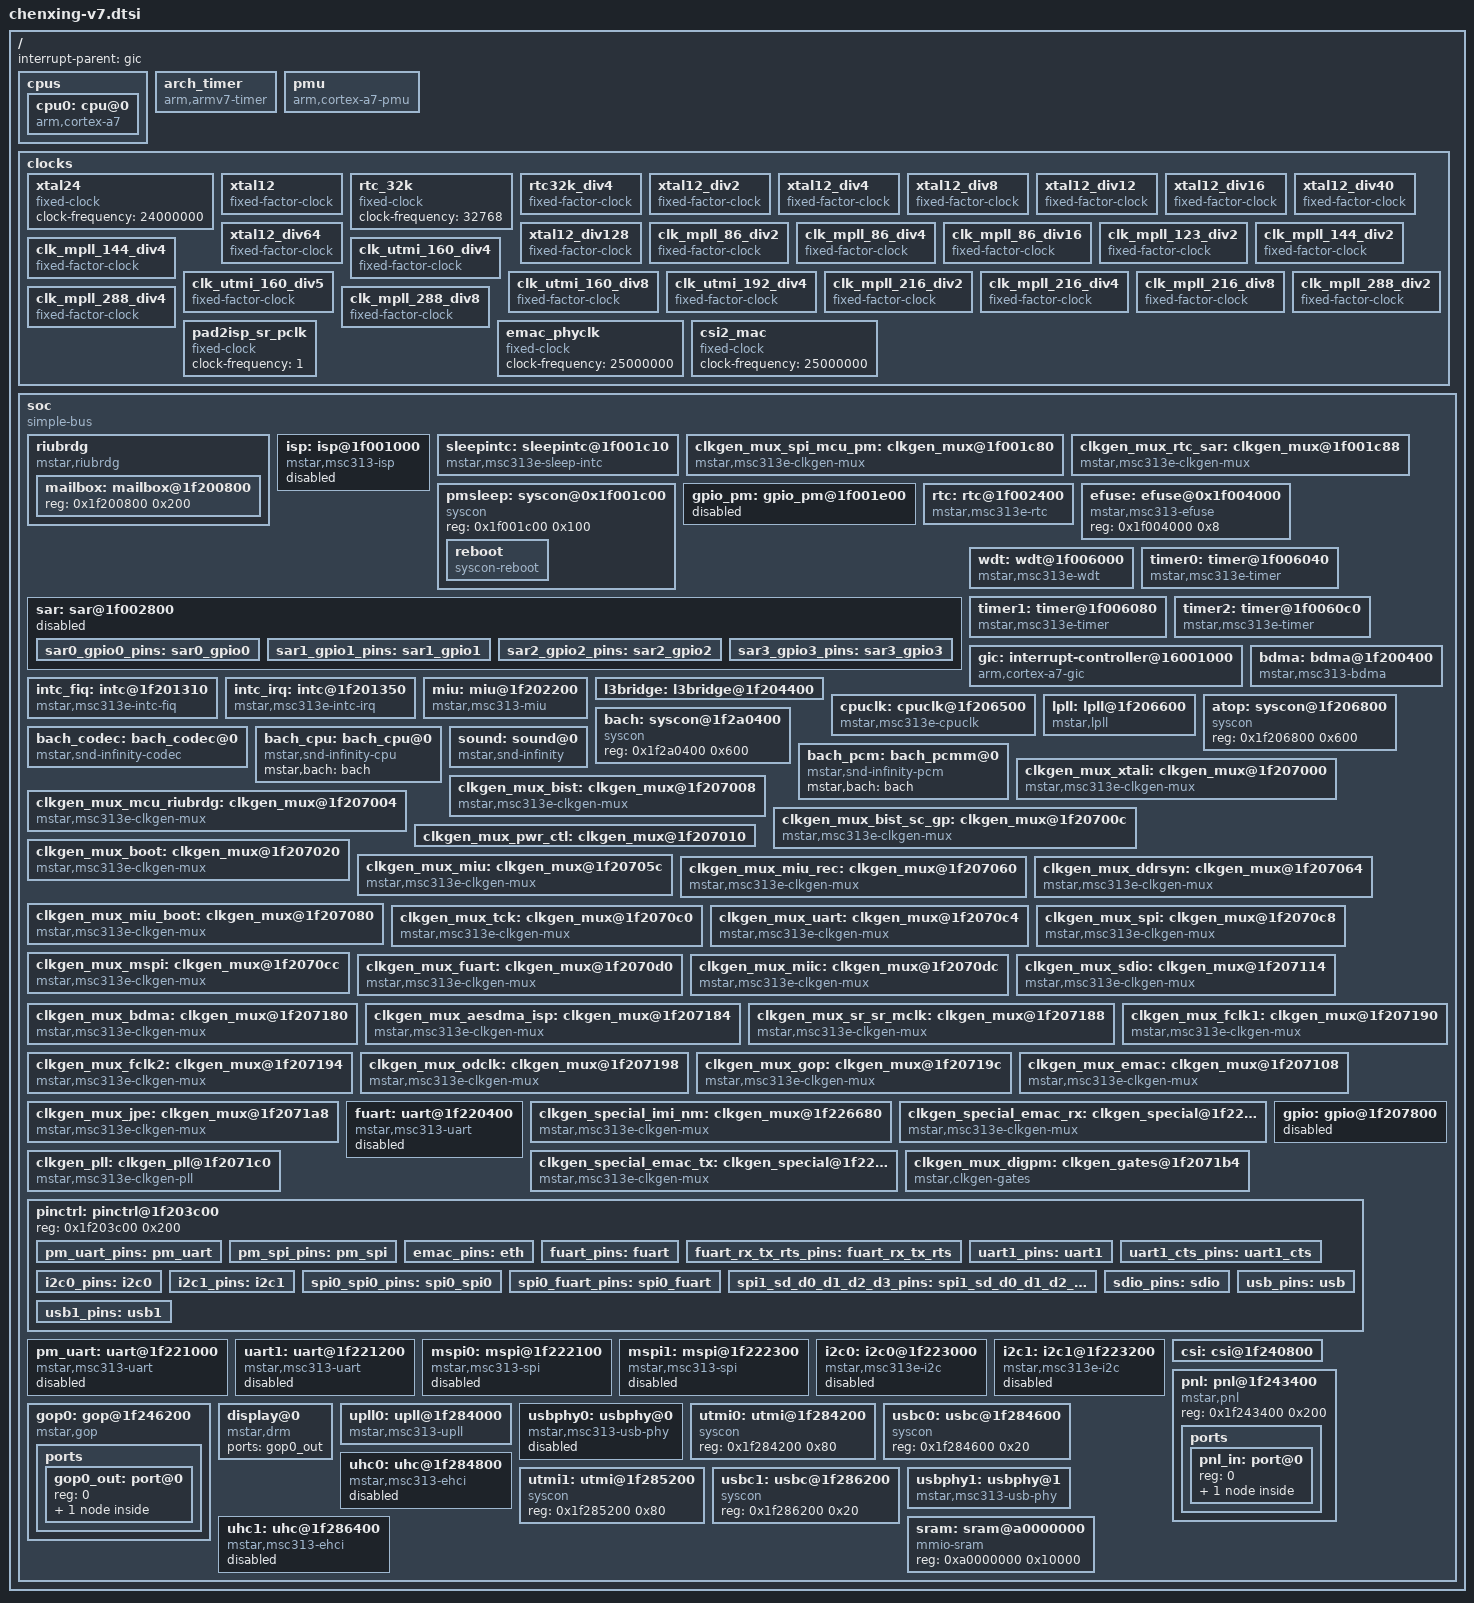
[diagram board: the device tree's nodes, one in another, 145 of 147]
// SPDX-License-Identifier: GPL-2.0
/*
 * Copyright (c) 2019 thingy.jp.
 * Author: Daniel Palmer <daniel@thingy.jp>
 */

#include <dt-bindings/interrupt-controller/irq.h>
#include <dt-bindings/interrupt-controller/arm-gic.h>
#include <dt-bindings/clock/mstar.h>

/ {
	#address-cells = <1>;
	#size-cells = <1>;
	interrupt-parent = <&gic>;

	cpus {
		#address-cells = <1>;
		#size-cells = <0>;

		cpu0: cpu@0 {
			device_type = "cpu";
			compatible = "arm,cortex-a7";
			reg = <0x0>;
			clocks = <&cpuclk>;
			clock-names = "cpuclk";
		};
	};

	arch_timer {
		compatible = "arm,armv7-timer";
		interrupts = <GIC_PPI 13 (GIC_CPU_MASK_SIMPLE(2)
				| IRQ_TYPE_LEVEL_LOW)>,
			     <GIC_PPI 14 (GIC_CPU_MASK_SIMPLE(2)
				| IRQ_TYPE_LEVEL_LOW)>,
			     <GIC_PPI 11 (GIC_CPU_MASK_SIMPLE(2)
				| IRQ_TYPE_LEVEL_LOW)>,
			     <GIC_PPI 10 (GIC_CPU_MASK_SIMPLE(2)
				| IRQ_TYPE_LEVEL_LOW)>;
		clock-frequency = <6000000>;
	};

	pmu {
		compatible = "arm,cortex-a7-pmu";
		interrupts = <GIC_SPI 10 IRQ_TYPE_LEVEL_HIGH>,
			     <GIC_SPI 16 IRQ_TYPE_LEVEL_HIGH>,
			     <GIC_SPI 22 IRQ_TYPE_LEVEL_HIGH>,
			     <GIC_SPI 28 IRQ_TYPE_LEVEL_HIGH>;
	};

	clocks: clocks {
		/*
		 * For the msc313e there is only a 24mhz clock input so everything else must come
		 * from this base clock unless there are some on-die oscillators that aren't mentioned
		 * anywhere.
		 */
		xtal24: xtal24 {
			#clock-cells = <0>;
			compatible = "fixed-clock";
			clock-frequency = <24000000>;
		};

		xtal12: xtal12 {
			#clock-cells = <0>;
			compatible = "fixed-factor-clock";
			clocks = <&xtal24>;
			clock-div = <2>;
			clock-mult = <1>;
		};

		rtc_32k: rtc_32k {
			#clock-cells = <0>;
			compatible = "fixed-clock";
			clock-frequency = <32768>;
		};

		rtc32k_div4: rtc32k_div4 {
			compatible = "fixed-factor-clock";
			#clock-cells = <0>;
			clocks = <&rtc_32k>;
			clock-div = <4>;
			clock-mult = <1>;
		};

		xtal12_div2: xtal12_div2 {
			compatible = "fixed-factor-clock";
			#clock-cells = <0>;
			clocks = <&xtal12>;
			clock-div = <2>;
			clock-mult = <1>;
		};

		xtal12_div4: xtal12_div4 {
			compatible = "fixed-factor-clock";
			#clock-cells = <0>;
			clocks = <&xtal12>;
			clock-div = <4>;
			clock-mult = <1>;
		};

		xtal12_div8: xtal12_div8 {
			compatible = "fixed-factor-clock";
			#clock-cells = <0>;
			clocks = <&xtal12>;
			clock-div = <8>;
			clock-mult = <1>;
		};

		xtal12_div12: xtal12_div12 {
			compatible = "fixed-factor-clock";
			#clock-cells = <0>;
			clocks = <&xtal12>;
			clock-div = <12>;
			clock-mult = <1>;
		};

		xtal12_div16: xtal12_div16 {
			compatible = "fixed-factor-clock";
			#clock-cells = <0>;
			clocks = <&xtal12>;
			clock-div = <16>;
			clock-mult = <1>;
		};

		xtal12_div40: xtal12_div40 {
			compatible = "fixed-factor-clock";
			#clock-cells = <0>;
			clocks = <&xtal12>;
			clock-div = <40>;
			clock-mult = <1>;
		};

		xtal12_div64: xtal12_div64 {
			compatible = "fixed-factor-clock";
			#clock-cells = <0>;
			clocks = <&xtal12>;
			clock-div = <64>;
			clock-mult = <1>;
		};

		xtal12_div128: xtal12_div128 {
			compatible = "fixed-factor-clock";
			#clock-cells = <0>;
			clocks = <&xtal12>;
			clock-div = <128>;
			clock-mult = <1>;
		};

		clk_mpll_86_div2: clk_mpll_86_div2 {
			compatible = "fixed-factor-clock";
			#clock-cells = <0>;
			clocks = <&clkgen_pll MSTAR_MPLL_GATE_MPLL_86>;
			clock-div = <2>;
			clock-mult = <1>;
		};

		clk_mpll_86_div4: clk_mpll_86_div4 {
			compatible = "fixed-factor-clock";
			#clock-cells = <0>;
			clocks = <&clkgen_pll MSTAR_MPLL_GATE_MPLL_86>;
			clock-div = <4>;
			clock-mult = <1>;
		};

		clk_mpll_86_div16: clk_mpll_86_div16 {
			compatible = "fixed-factor-clock";
			#clock-cells = <0>;
			clocks = <&clkgen_pll MSTAR_MPLL_GATE_MPLL_86>;
			clock-div = <16>;
			clock-mult = <1>;
		};

		clk_mpll_123_div2: clk_mpll_123_div2 {
			compatible = "fixed-factor-clock";
			#clock-cells = <0>;
			clocks = <&clkgen_pll MSTAR_MPLL_GATE_MPLL_123>;
			clock-div = <2>;
			clock-mult = <1>;
		};

		clk_mpll_144_div2: clk_mpll_144_div2 {
			compatible = "fixed-factor-clock";
			#clock-cells = <0>;
			clocks = <&clkgen_pll MSTAR_MPLL_GATE_MPLL_144>;
			clock-div = <2>;
			clock-mult = <1>;
		};

		clk_mpll_144_div4: clk_mpll_144_div4 {
			compatible = "fixed-factor-clock";
			#clock-cells = <0>;
			clocks = <&clkgen_pll MSTAR_MPLL_GATE_MPLL_144>;
			clock-div = <4>;
			clock-mult = <1>;
		};

		clk_utmi_160_div4: clk_utmi_160_div4 {
			compatible = "fixed-factor-clock";
			#clock-cells = <0>;
			clocks = <&clkgen_pll MSTAR_MPLL_GATE_UTMI_160>;
			clock-div = <4>;
			clock-mult = <1>;
		};

		clk_utmi_160_div5: clk_utmi_160_div5 {
			compatible = "fixed-factor-clock";
			#clock-cells = <0>;
			clocks = <&clkgen_pll MSTAR_MPLL_GATE_UTMI_160>;
			clock-div = <5>;
			clock-mult = <1>;
		};

		clk_utmi_160_div8: clk_utmi_160_div8 {
			compatible = "fixed-factor-clock";
			#clock-cells = <0>;
			clocks = <&clkgen_pll MSTAR_MPLL_GATE_UTMI_160>;
			clock-div = <8>;
			clock-mult = <1>;
		};

		clk_utmi_192_div4: clk_utmi_192_div4 {
			compatible = "fixed-factor-clock";
			#clock-cells = <0>;
			clocks = <&clkgen_pll MSTAR_MPLL_GATE_UTMI_192>;
			clock-div = <4>;
			clock-mult = <1>;
		};

		clk_mpll_216_div2: clk_mpll_216_div2 {
			compatible = "fixed-factor-clock";
			#clock-cells = <0>;
			clocks = <&clkgen_pll MSTAR_MPLL_GATE_MPLL_216>;
			clock-div = <2>;
			clock-mult = <1>;
		};

		clk_mpll_216_div4: clk_mpll_216_div4 {
			compatible = "fixed-factor-clock";
			#clock-cells = <0>;
			clocks = <&clkgen_pll MSTAR_MPLL_GATE_MPLL_216>;
			clock-div = <4>;
			clock-mult = <1>;
		};

		clk_mpll_216_div8: clk_mpll_216_div8 {
			compatible = "fixed-factor-clock";
			#clock-cells = <0>;
			clocks = <&clkgen_pll MSTAR_MPLL_GATE_MPLL_216>;
			clock-div = <8>;
			clock-mult = <1>;
		};

		clk_mpll_288_div2: clk_mpll_288_div2 {
			compatible = "fixed-factor-clock";
			#clock-cells = <0>;
			clocks = <&clkgen_pll MSTAR_MPLL_GATE_MPLL_288>;
			clock-div = <2>;
			clock-mult = <1>;
		};

		clk_mpll_288_div4: clk_mpll_288_div4 {
			compatible = "fixed-factor-clock";
			#clock-cells = <0>;
			clocks = <&clkgen_pll MSTAR_MPLL_GATE_MPLL_288>;
			clock-div = <4>;
			clock-mult = <1>;
		};

		clk_mpll_288_div8: clk_mpll_288_div8 {
			compatible = "fixed-factor-clock";
			#clock-cells = <0>;
			clocks = <&clkgen_pll MSTAR_MPLL_GATE_MPLL_288>;
			clock-div = <8>;
			clock-mult = <1>;
		};

		emac_phyclk: emac_phyclk {
			#clock-cells = <0>;
			compatible = "fixed-clock";
			clock-frequency = <25000000>;
		};
		
		pad2isp_sr_pclk: pad2isp_sr_pclk {
			#clock-cells = <0>;
			compatible = "fixed-clock";
			clock-frequency = <1>;
		};
	
		csi2_mac: csi2_mac {
			#clock-cells = <0>;
			compatible = "fixed-clock";
			clock-frequency = <25000000>;
		};
	};

	soc: soc {
		compatible = "simple-bus";
		#address-cells = <1>;
		#size-cells = <1>;
		ranges;

		riubrdg: riubrdg {
			compatible = "mstar,riubrdg";
			#address-cells = <1>;
			#size-cells = <1>;
			ranges;
			clocks = <&clkgen_mux_mcu_riubrdg 1>;
			interrupts-extended = <&intc_irq 51 IRQ_TYPE_LEVEL_HIGH>;

			mailbox: mailbox@1f200800 {
				reg = <0x1f200800 0x200>;
				/*
				 * 0x0 - boot rom writes 0xbabe here right near the start.
				 */
			};
		};

		isp: isp@1f001000 {
			compatible = "mstar,msc313-isp";
			reg = <0x1f001000 0x400>,
			      <0x1f002c00 0x200>,
			      <0x1f002e00 0x200>,
			      <0x14000000 0x1000000>;
			clocks = <&clkgen_mux_aesdma_isp 1>;
			interrupts-extended = <&intc_irq 5 IRQ_TYPE_LEVEL_HIGH>;
			dmas = <&bdma 0>, <&bdma 1>;
			dma-names = "qspi", "qspi";
			pinctrl-names = "default";
			pinctrl-0 = <&pm_spi_pins>;
			status = "disabled";
		};

		sleepintc: sleepintc@1f001c10 {
			compatible = "mstar,msc313e-sleep-intc";
			reg = <0x1f001c10 0x8>;
			interrupts-extended = <&intc_irq 2 IRQ_TYPE_LEVEL_HIGH>;
			interrupt-controller;
			#interrupt-cells = <2>;
		};

		clkgen_mux_spi_mcu_pm: clkgen_mux@1f001c80 {
			compatible = "mstar,msc313e-clkgen-mux";
			reg = <0x1f001c80 0x4>;
			#clock-cells = <1>;
			clock-output-names = "mcu_pm", "spi_pm";
			shifts = <0>, <8>;
			mux-shifts = <2>, <10>;
			mux-widths = <4>, <4>;
			mux-ranges = <0 1>, <1 16>;
			clocks = /* mcu_pm */
				 <&clkgen_pll MSTAR_MPLL_GATE_MPLL_216>,
				 /* spi_pm */
				 <&rtc_32k>,
				 <&clk_mpll_216_div8>,
				 <&clk_mpll_144_div4>,
				 <&clk_mpll_86_div2>,
				 <&clk_mpll_216_div4>,
				 <&clk_mpll_144_div2>,
				 <&clkgen_pll MSTAR_MPLL_GATE_MPLL_86>,
				 <&clk_mpll_216_div2>,
				 <&xtal12_div8>,
				 <&xtal12_div12>,
				 <&rtc32k_div4>,
				 <&xtal12_div16>,
				 <&xtal12_div2>,
				 <&xtal12_div4>,
				 <&xtal12>,
				 <&xtal24>;
		};

		clkgen_mux_rtc_sar: clkgen_mux@1f001c88 {
			compatible = "mstar,msc313e-clkgen-mux";
			reg = <0x1f001c88 0x4>;
			#clock-cells = <1>;
			clock-output-names = "rtc", "sar", "pm_sleep";
			shifts = <0>, <5>, <10>;
			mux-shifts = <2>, <7>, <12>;
			mux-widths = <2>, <3>, <3>;
			mux-ranges = <0 2>, <0 8>, <0 8>;
			clocks = <&clkgen_mux_xtali 0>,
					 <&rtc_32k>,
					 <&xtal12_div8>,
					 <&xtal12_div12>,
					 <&rtc32k_div4>,
					 <&xtal12_div16>,
					 <&xtal12_div2>,
					 <&xtal12_div4>;
		};

		pmsleep: syscon@0x1f001c00 {
			/* msc313e notes */
			/* 0x1f001c00 - wake up source */
			/*
			 * 1f001c24 -- bit 11 disables pm uart rx
			 * -- bit 15 is set when going into deep sleep
			 *
			 * mysteryclk1 1f001cf4
			 * 0x1f001cc0 -- ??
			 * 0x1f001cc8  -- set to 9fe8 before deep sleep
			 * 0x1f001ccc  -- set to 9fe8 before deep sleep
			 * 0x1f001cdc  -- set to 0xa5 before deep sleep
		         *
			 * 0x1f001c70  -- set to 0x0c before deep sleep
			 * 0x1f001c48  -- set to 0xbabe before deep sleep
			 *
			 * 0x1f001cec -- return address after resume
			 * 0x1f001cf0
			 * 0x1f001cf4 -- clk for timers?
			 * 0x1f001cb8 - writing 0x79 triggers a cpu reset
			 * 0x1f001cbc - bit 3 in here controls something to do with the temp sensor
			 */
			compatible = "syscon";
			reg = <0x1f001c00 0x100>;

			reboot {
				compatible = "syscon-reboot";
				regmap = <&pmsleep>;
				offset = <0xb8>;
				mask = <0x79>;
			};
		};

		gpio_pm: gpio_pm@1f001e00 {
			reg = <0x1f001e00 0x200>;
			#gpio-cells = <2>;
			gpio-controller;
			interrupt-controller;
			#interrupt-cells = <3>;
			interrupt-parent = <&sleepintc>;
			status = "disabled";
		};



		rtc: rtc@1f002400 {
			compatible = "mstar,msc313e-rtc";
			reg = <0x1f002400 0x40>;
			clocks = <&clkgen_mux_rtc_sar 0>;
			interrupt-parent = <&intc_irq>;
			interrupts = <44 IRQ_TYPE_LEVEL_HIGH>;
		};

		sar: sar@1f002800 {
			reg = <0x1f002800 0x200>;
			interrupts-extended = <&intc_irq 45 IRQ_TYPE_LEVEL_HIGH>,
					      <&intc_fiq 24 IRQ_TYPE_LEVEL_HIGH>,
					      <&intc_fiq 25 IRQ_TYPE_LEVEL_HIGH>,
					      <&intc_fiq 26 IRQ_TYPE_LEVEL_HIGH>,
					      <&intc_fiq 27 IRQ_TYPE_LEVEL_HIGH>;
			interrupt-names = "sar",
					  "sar_gpio0",
					  "sar_gpio1",
					  "sar_gpio2",
					  "sar_gpio3";
			clock-names = "sar_clk";
			clocks = <&clkgen_mux_rtc_sar 1>;
			mstar,pmsleep = <&pmsleep>;
			status = "disabled";
			#gpio-cells = <2>;
			sar0_gpio0_pins: sar0_gpio0 {
				function = "sar0";
				groups = "sar_gpio0";
			};
			sar1_gpio1_pins: sar1_gpio1 {
				function = "sar1";
				groups = "sar_gpio1";
			};
			sar2_gpio2_pins: sar2_gpio2 {
				function = "sar2";
				groups = "sar_gpio2";
			};
			sar3_gpio3_pins: sar3_gpio3 {
				function = "sar3";
				groups = "sar_gpio3";
			};
		};

		/*
		temp_sensor {
			compatible = "iio-hwmon";
			io-channels = <&sar 4>;
		};
		*/

		efuse: efuse@0x1f004000 {
			compatible = "mstar,msc313-efuse";
			reg = <0x1f004000 0x8>;
		};

		wdt: wdt@1f006000 {
			compatible = "mstar,msc313e-wdt";
			reg = <0x1f006000 0x1f>;
			clocks = <&xtal12>;
			interrupts-extended = <&intc_fiq 2 IRQ_TYPE_LEVEL_HIGH>;
		};

		timer0: timer@1f006040 {
			compatible = "mstar,msc313e-timer";
			reg = <0x1f006040 0x40>;
			clocks = <&xtal12>;
			interrupts-extended = <&intc_fiq 0 IRQ_TYPE_LEVEL_HIGH>;
		};

		timer1: timer@1f006080 {
			compatible = "mstar,msc313e-timer";
			reg = <0x1f006080 0x40>;
			clocks = <&xtal12>;
			interrupts-extended = <&intc_fiq 1 IRQ_TYPE_LEVEL_HIGH>;
		};

		timer2: timer@1f0060c0 {
			compatible = "mstar,msc313e-timer";
			reg = <0x1f0060c0 0x40>;
			clocks = <&xtal12>;
			interrupts-extended = <&intc_fiq 12 IRQ_TYPE_LEVEL_HIGH>;
		};

		gic: interrupt-controller@16001000 {
			compatible = "arm,cortex-a7-gic";
			#interrupt-cells = <3>;
			#address-cells = <1>;
			#size-cells = <1>;
			interrupt-controller;
			reg = <0x16001000 0x1000>,
			      <0x16002000 0x1000>;
		};

		bdma: bdma@1f200400 {
			compatible = "mstar,msc313-bdma";
			reg = <0x1f200400 0x80>;
			interrupt-parent = <&intc_irq>;
			interrupts = <40 IRQ_TYPE_LEVEL_HIGH>,
				     <41 IRQ_TYPE_LEVEL_HIGH>;
			clocks = <&clkgen_mux_bdma 0>;
			status = "okay";
			#dma-cells = <1>;
		};

		intc_fiq: intc@1f201310 {
			compatible = "mstar,msc313e-intc-fiq";
			interrupt-controller;
			reg = <0x1f201310 0x40>;
			#interrupt-cells = <2>;
			interrupt-parent = <&gic>;
			gic-offset = <96>;
			nr-interrupts = <32>;
		};

		intc_irq: intc@1f201350 {
			compatible = "mstar,msc313e-intc-irq";
			interrupt-controller;
			reg = <0x1f201350 0x40>;
			#interrupt-cells = <2>;
			interrupt-parent = <&gic>;
			gic-offset = <32>;
			nr-interrupts = <64>;
		};

		miu: miu@1f202200 {
			compatible = "mstar,msc313-miu";
			reg = <0x1f202000 100>,
			      /*<0x1f202200 100>,*/
			      <0x1f202400 100>;
			interrupt-parent = <&intc_irq>;
			interrupts = <49 IRQ_TYPE_LEVEL_HIGH>;
			clock-names = "miu", "ddr";
			clocks = <&clkgen_mux_miu 0>, <&clkgen_mux_ddrsyn 0>;
			/*mstar,rd-timing = <0xB>;*/
			mstar,trcd = <0x6>;
			mstar,trp = <0x6>;
		};

		l3bridge: l3bridge@1f204400 {
			/*1f204414 - cache flush*/
			/*1f204440 - status */
		};

		cpuclk: cpuclk@1f206500 {
			compatible = "mstar,msc313e-cpuclk";
			reg = <0x1f206500 0x100>;
			#clock-cells = <0>;
			clocks = <&clkgen_pll MSTAR_MPLL_GATE_MPLL_432>;
		};

		lpll: lpll@1f206600 {
			compatible = "mstar,lpll";
			reg = <0x1f206600 0x200>;
			#clock-cells = <0>;
			clocks = <&clkgen_pll MSTAR_MPLL_GATE_MPLL_432>;
		};

		atop: syscon@1f206800 {
			compatible = "syscon";
			reg = <0x1f206800 0x600>;
		};

		/* bach */
		bach: syscon@1f2a0400 {
			compatible = "syscon";
			reg = <0x1f2a0400 0x600>;
		};

		bach_codec: bach_codec@0 {
			compatible = "mstar,snd-infinity-codec";
			mstar,atop = <&atop>;
			mstar,bach = <&bach>;
		};

		bach_cpu: bach_cpu@0 {
			compatible = "mstar,snd-infinity-cpu";
			mstar,bach = <&bach>;
		};

		bach_pcm: bach_pcmm@0 {
			compatible = "mstar,snd-infinity-pcm";
			mstar,bach = <&bach>;
		};

		sound: sound@0 {
			compatible = "mstar,snd-infinity";
			interrupt-parent = <&intc_irq>;
			interrupts = <42 IRQ_TYPE_LEVEL_HIGH>;
			mstar,bach-cpu = <&bach_cpu>;
			mstar,bach-platform = <&bach_pcm>;
			mstar,bach-codec = <&bach_codec>;
		};
		/* */

		// gating xtali stops interrupts from the
		// arch timer
		clkgen_mux_xtali: clkgen_mux@1f207000 {
			compatible = "mstar,msc313e-clkgen-mux";
			reg = <0x1f207000 0x4>;
			#clock-cells = <1>;
			clock-output-names = "xtali", "xtali_sc_gp", "live";
			output-flags = <MSTAR_CLKGEN_OUTPUTFLAG_CRITICAL>, <0x0>, <0x0>;
			shifts = <0>, <4>, <8>;
			mux-shifts = <2>, <6>, <10>;
			mux-widths = <2>, <2>, <2>;
			clocks = <&xtal12>;
		};

		clkgen_mux_mcu_riubrdg: clkgen_mux@1f207004 {
			compatible = "mstar,msc313e-clkgen-mux";
			reg = <0x1f207004 0x4>;
			#clock-cells = <1>;
			clock-output-names = "mcu", "riubrdg";
			shifts = <0>, <8>;
			mux-shifts = <2>, <10>;
			mux-widths = <2>, <2>;
			mux-ranges = <0 4 >, <4 1>;
			output-flags = <0>, <MSTAR_CLKGEN_OUTPUTFLAG_CRITICAL>;
			clocks = <&clkgen_pll MSTAR_MPLL_GATE_MPLL_216>,
				 <&clkgen_pll MSTAR_MPLL_GATE_MPLL_172>,
				 <&clk_mpll_288_div2>,
				 <&clk_mpll_216_div2>,
				 <&clkgen_mux_mcu_riubrdg 0>;
		};

		clkgen_mux_bist: clkgen_mux@1f207008 {
			compatible = "mstar,msc313e-clkgen-mux";
			reg = <0x1f207008 0x4>;
			#clock-cells = <1>;
			clock-output-names = "bist";
			shifts = <0>;
			mux-shifts = <2>;
			mux-widths = <2>;
			clocks = <&clkgen_pll MSTAR_MPLL_GATE_MPLL_172>,
				 <&clk_mpll_216_div2>,
				 <&clk_mpll_216_div4>,
				 <&xtal12>;
		};

		clkgen_mux_bist_sc_gp: clkgen_mux@1f20700c {
			compatible = "mstar,msc313e-clkgen-mux";
			reg = <0x1f20700c 0x4>;
			#clock-cells = <1>;
			clock-output-names = "bist_sc_gp";
			shifts = <0>;
			mux-shifts = <2>;
			mux-widths = <2>;
			clocks = <&clkgen_pll MSTAR_MPLL_GATE_MPLL_172>,
				 <&clk_mpll_216_div2>,
				 <&clk_mpll_216_div4>,
				 <&xtal12>;
		};

		/* can't write on i3, i6 only? */
		clkgen_mux_pwr_ctl: clkgen_mux@1f207010 {
			// pwr_ctrl
			// 
		};

		// this one is interesting, looks like
		// the clock thats used to deglitch
		clkgen_mux_boot: clkgen_mux@1f207020 {
			compatible = "mstar,msc313e-clkgen-mux";
			reg = <0x1f207020 0x4>;
			#clock-cells = <1>;
			clock-output-names = "boot";
			shifts = <0>;
			mux-shifts = <2>;
			mux-widths = <2>;
			clocks = <&xtal12>;
		};

		clkgen_mux_miu: clkgen_mux@1f20705c {
			compatible = "mstar,msc313e-clkgen-mux";
			reg = <0x1f20705c 0x4>;
			#clock-cells = <1>;
			clock-output-names = "miu";
			output-flags = <MSTAR_CLKGEN_OUTPUTFLAG_CRITICAL>;
			shifts = <0>;
			mux-shifts = <2>;
			mux-widths = <2>;
			clocks = <&clkgen_mux_ddrsyn 0>;
		};

		clkgen_mux_miu_rec: clkgen_mux@1f207060 {
			compatible = "mstar,msc313e-clkgen-mux";
			reg = <0x1f207060 0x4>;
			#clock-cells = <1>;
			clock-output-names = "miu_rec";
			shifts = <0>;
			mux-shifts = <2>;
			mux-widths = <2>;
			clocks = <&xtal12_div8>,
				 <&xtal12_div16>,
				 <&xtal12_div64>,
				 <&xtal12_div128>;
		};

		clkgen_mux_ddrsyn: clkgen_mux@1f207064 {
			compatible = "mstar,msc313e-clkgen-mux";
			reg = <0x1f207064 0x4>;
			#clock-cells = <1>;
			clock-output-names = "ddrsyn";
			output-flags = <MSTAR_CLKGEN_OUTPUTFLAG_CRITICAL>;
			shifts = <0>;
			mux-shifts = <2>;
			mux-widths = <2>;
			clocks = <&clkgen_pll MSTAR_MPLL_GATE_MPLL_432>,
				 <&clkgen_pll MSTAR_MPLL_GATE_MPLL_216>,
				 <&xtal12>;
		};

		clkgen_mux_miu_boot: clkgen_mux@1f207080 {
			compatible = "mstar,msc313e-clkgen-mux";
			reg = <0x1f207080 0x4>;
			#clock-cells = <1>;
			clock-output-names = "miu_boot";
			shifts = <0>;
			mux-shifts = <2>;
			mux-widths = <2>;
			clocks = <&xtal12>,
				 <&clkgen_mux_miu 0>;
		};

		/* This seems important as the ipl turns it on at boot.
		 * Maybe tck == test clock? for JTAG?
		 */
		clkgen_mux_tck: clkgen_mux@1f2070c0 {
			compatible = "mstar,msc313e-clkgen-mux";
			reg = <0x1f2070c0 0x4>;
			#clock-cells = <1>;
			clock-output-names = "tck";
			shifts = <0>;
		};

		clkgen_mux_uart: clkgen_mux@1f2070c4 {
			compatible = "mstar,msc313e-clkgen-mux";
			reg = <0x1f2070c4 0x4>;
			#clock-cells = <1>;
			clock-output-names = "uart0", "uart1";
			shifts = <0>, <8>;
			mux-shifts = <2>, <10>;
			mux-widths = <2>, <2>;
			clocks = <&clkgen_pll MSTAR_MPLL_GATE_MPLL_172>,
				 <&clk_mpll_288_div2>,
				 <&xtal12>;
		};

		clkgen_mux_spi: clkgen_mux@1f2070c8 {
			compatible = "mstar,msc313e-clkgen-mux";
			reg = <0x1f2070c8 0x4>;
			#clock-cells = <1>;
			clock-output-names = "spi"; 
			shifts = <0>;
			mux-shifts = <2>;
			mux-widths = <2>;
			clocks = <&clkgen_pll MSTAR_MPLL_GATE_MPLL_216>,
				 <&clk_mpll_216_div2>,
				 <&clkgen_pll MSTAR_MPLL_GATE_MPLL_86>,
			         <&clk_mpll_288_div4>;
		};

		clkgen_mux_mspi: clkgen_mux@1f2070cc {
			compatible = "mstar,msc313e-clkgen-mux";
			reg = <0x1f2070cc 0x4>;
			#clock-cells = <1>;
			clock-output-names = "mspi0", "mspi1"; 
			shifts = <0>, <8>;
			mux-shifts = <2>, <10>;
			mux-widths = <2>, <2>;
			clocks = <&clk_mpll_216_div2>,
			         <&clk_mpll_216_div4>,
			         <&xtal12>;
		};

		clkgen_mux_fuart: clkgen_mux@1f2070d0 {
			compatible = "mstar,msc313e-clkgen-mux";
			reg = <0x1f2070d0 0x4>;
			#clock-cells = <1>;
			clock-output-names = "fuart", "fuart0_synth";
			shifts = <0>, <4>;
			mux-shifts = <2>, <6>;
			mux-widths = <2>, <2>;
			mux-ranges = <0 5>, <5 2>;
			clocks = <&clkgen_pll 10>,
					 <&clk_mpll_216_div2>,
			         <&clk_mpll_216_div4>,
			         <&xtal12>,
			         <&clkgen_mux_fuart 1>,
			         /* synth*/
			         <&clkgen_pll MSTAR_MPLL_GATE_MPLL_432>,
			         <&clkgen_pll MSTAR_MPLL_GATE_MPLL_216>;
		};

		clkgen_mux_miic: clkgen_mux@1f2070dc {
			compatible = "mstar,msc313e-clkgen-mux";
			reg = <0x1f2070dc 0x4>;
			#clock-cells = <1>;
			clock-output-names = "miic0", "miic1";
			shifts = <0>, <8>;
			mux-shifts = <2>, <10>;
			mux-widths = <2>, <2>;
			clocks = <&clk_mpll_288_div4>,
				 <&clk_mpll_216_div4>,
				 <&xtal12>;
		};

		clkgen_mux_sdio: clkgen_mux@1f207114 {
			compatible = "mstar,msc313e-clkgen-mux";
			reg = <0x1f207114 0x4>;
			#clock-cells = <1>;
			clock-output-names = "sdio";
			shifts = <0>;
			mux-shifts = <2>;
			mux-widths = <3>;
			clocks = <&clk_utmi_192_div4>,
				 <&clk_mpll_86_div2>,
				 <&clk_utmi_160_div4>,
				 <&clk_mpll_288_div8>,
				 <&clk_utmi_160_div5>,
				 <&clk_utmi_160_div8>,
				 <&xtal12>,
				 <&xtal12_div40>;
		};

		clkgen_mux_bdma: clkgen_mux@1f207180 {
			compatible = "mstar,msc313e-clkgen-mux";
			reg = <0x1f207180 0x4>;
			#clock-cells = <1>;
			clock-output-names = "bdma";
			shifts = <0>;
			mux-shifts = <2>;
			mux-widths = <2>;
			clocks = <&clkgen_mux_miu 0>;
		};

		clkgen_mux_aesdma_isp: clkgen_mux@1f207184 {
			compatible = "mstar,msc313e-clkgen-mux";
			reg = <0x1f207184 0x4>;
			#clock-cells = <1>;
			clock-output-names = "aesdma", "isp";
			shifts = <0>, <8>;
			mux-shifts = <2>, <10>;
			mux-widths = <2>, <2>;
			mux-ranges = <0 2>, <2 4>;
			clocks = /* aesdma */
				<&clkgen_pll MSTAR_MPLL_GATE_MPLL_86>,
				<&clkgen_pll MSTAR_MPLL_GATE_MPLL_172>,
				/* isp */
				<&clkgen_pll MSTAR_MPLL_GATE_MPLL_123>,
				<&clkgen_pll MSTAR_MPLL_GATE_MPLL_86>,
				<&clk_mpll_288_div4>,
				<&clk_mpll_216_div4>;
		};

		clkgen_mux_sr_sr_mclk: clkgen_mux@1f207188 {
			compatible = "mstar,msc313e-clkgen-mux";
			reg = <0x1f207188 0x4>;
			#clock-cells = <1>;
			clock-output-names = "sr", "sr_mclk";
			shifts = <0>, <8>;
			mux-shifts = <2>, <10>;
			mux-widths = <2>, <3>;
			mux-ranges = <0 4>, <4 8>;
			clocks =
			/* sr */
			<&pad2isp_sr_pclk>,
			<&csi2_mac>,
			<&clk_utmi_160_div4>,
			<&clkgen_pll MSTAR_MPLL_GATE_MPLL_86>,
			/* sr_mclk */
			<&clk_mpll_216_div8>,
			<&clk_mpll_86_div4>,
			<&xtal12>,
			<&clk_mpll_86_div16>,
			<&clk_mpll_288_div8>,
			<&clk_mpll_216_div4>,
			<&clk_mpll_86_div2>,
			<&clk_mpll_123_div2>;
		};

		clkgen_mux_fclk1: clkgen_mux@1f207190 {
			compatible = "mstar,msc313e-clkgen-mux";
			reg = <0x1f207190 0x4>;
			#clock-cells = <1>;
			clock-output-names = "fclk1";
			shifts = <0>;
			mux-shifts = <2>;
			mux-widths = <2>;
			clocks = <&clkgen_pll MSTAR_MPLL_GATE_MPLL_172>,
				 <&clkgen_pll MSTAR_MPLL_GATE_MPLL_86>;
		};

		clkgen_mux_fclk2: clkgen_mux@1f207194 {
			compatible = "mstar,msc313e-clkgen-mux";
			reg = <0x1f207194 0x4>;
			#clock-cells = <1>;
			clock-output-names = "fclk2";
			shifts = <0>;
			mux-shifts = <2>;
			mux-widths = <2>;
			clocks = <&clkgen_pll MSTAR_MPLL_GATE_MPLL_172>,
				 <&clkgen_pll MSTAR_MPLL_GATE_MPLL_86>;
		};

		clkgen_mux_odclk: clkgen_mux@1f207198 {
			compatible = "mstar,msc313e-clkgen-mux";
			reg = <0x1f207198 0x4>;
			#clock-cells = <1>;
			clock-output-names = "odclk";
			shifts = <0>;
			mux-shifts = <2>;
			mux-widths = <2>;
			clocks = <&clkgen_pll MSTAR_MPLL_GATE_MPLL_86>,
				 <&clk_mpll_86_div2>,
				 <&clk_mpll_86_div4>,
				 <&lpll>;
		};

		clkgen_mux_gop: clkgen_mux@1f20719c {
			compatible = "mstar,msc313e-clkgen-mux";
			reg = <0x1f20719c 0x4>;
			#clock-cells = <1>;
			clock-output-names = "gop";
			shifts = <0>;
			mux-shifts = <2>;
			mux-widths = <2>;
			clocks = <&clkgen_mux_fclk1 0>; // might be incorrect
		};

		clkgen_mux_emac: clkgen_mux@1f207108 {
			compatible = "mstar,msc313e-clkgen-mux";
			reg = <0x1f207108 0x4>;
			#clock-cells = <1>;
			clock-output-names = "emac_ahb";
			shifts = <0>;
			mux-shifts = <2>;
			mux-widths = <2>;
			output-flags = <0x800>; /* this marks the clock as critical, gating this clock stops access to the registers */
			clocks = <&clk_mpll_288_div2>,
				 <&clkgen_pll MSTAR_MPLL_GATE_MPLL_123>,
				 <&clkgen_pll MSTAR_MPLL_GATE_MPLL_86>;
				 /* from lan_atop ? */
		};

		clkgen_mux_jpe: clkgen_mux@1f2071a8 {
			compatible = "mstar,msc313e-clkgen-mux";
			reg = <0x1f2071a8 0x4>;
			#clock-cells = <1>;
			clock-output-names = "jpe";
			shifts = <0>;
			mux-shifts = <2>;
			mux-widths = <2>;
			clocks = <&clkgen_pll MSTAR_MPLL_GATE_MPLL_288>,
				 <&clkgen_pll MSTAR_MPLL_GATE_MPLL_216>,
				 <&clk_mpll_216_div4>,
				 <&clk_mpll_216_div8>;
		};

		fuart: uart@1f220400 {
			compatible = "mstar,msc313-uart";
			reg = <0x1f220400 0x100>;
			/*
			 * DMA registers
			 * <0x1f220600 0x100>
			 */
			interrupt-parent = <&intc_irq>;
			interrupts = <47 IRQ_TYPE_LEVEL_HIGH>;
			reg-shift = <3>;
			clocks = <&clkgen_mux_fuart 0>;
			pinctrl-names = "default";
			pinctrl-0 = <&fuart_pins>;
			status = "disabled";
		};

		clkgen_special_imi_nm: clkgen_mux@1f226680 {
			compatible = "mstar,msc313e-clkgen-mux";
			reg = <0x1f226680 0x4>;
			#clock-cells = <1>;
			clock-output-names = "imi", "nlm";
			shifts = <0>, <8>;
			clocks = <&clkgen_pll 10>; /* this is wrong */
		};

		clkgen_special_emac_rx: clkgen_special@1f226688 {
			compatible = "mstar,msc313e-clkgen-mux";
			reg = <0x1f226688 0x4>;
			#clock-cells = <1>;
			clock-output-names = "emac_rx", "emac_rx_ref";
			shifts = <0>, <8>;
			mux-shifts = <2>, <10>;
			mux-widths = <2>, <2>;
			output-flags = <MSTAR_CLKGEN_OUTPUTFLAG_CRITICAL>;
			clocks = <&emac_phyclk>; /* imcomplete */
		};

		clkgen_special_emac_tx: clkgen_special@1f22668c {
			compatible = "mstar,msc313e-clkgen-mux";
			reg = <0x1f22668c 0x4>;
			#clock-cells = <1>;
			clock-output-names = "emac_tx", "emac_tx_ref";
			shifts = <0>, <8>;
			mux-shifts = <2>, <10>;
			mux-widths = <2>, <2>;
			output-flags = <MSTAR_CLKGEN_OUTPUTFLAG_CRITICAL>;
			clocks = <&emac_phyclk>; /* imcomplete */
		};

		// gating 216_2digpm stops the system
		clkgen_mux_digpm: clkgen_gates@1f2071b4 {
			compatible = "mstar,clkgen-gates";
			reg = <0x1f2071b4 0x4>;
			#clock-cells = <1>;
			clock-output-names = "hemcu_216",
					     "216_2digpm", 
					     "172_2digpm",
					     "144_2digpm",
					     "123_2digpm",
					     "86_2digpm";
			shifts = <0>, <1>, <2>, <3>, <4>, <5>;
			clocks = <&clkgen_pll MSTAR_MPLL_GATE_MPLL_216>,
				 <&clkgen_pll MSTAR_MPLL_GATE_MPLL_216>,
				 <&clkgen_pll MSTAR_MPLL_GATE_MPLL_172>,
				 <&clkgen_pll MSTAR_MPLL_GATE_MPLL_144>,
				 <&clkgen_pll MSTAR_MPLL_GATE_MPLL_123>,
				  <&clkgen_pll MSTAR_MPLL_GATE_MPLL_86>;
			output-flags = <0>, <MSTAR_CLKGEN_OUTPUTFLAG_CRITICAL>,
				       <0>, <0>, <0>, <0>;
		};

		/* this should be renamed to clk gates or something */
		clkgen_pll: clkgen_pll@1f2071c0 {
			compatible = "mstar,msc313e-clkgen-pll";
			reg = <0x1f2071c0 0x10>;
			#clock-cells = <1>;
			clock-output-names = "upll_384", "upll_320", "utmi_160", "utmi_192",
					     "utmi_240", "utmi_480", "mpll_432", "mpll_345",
					     "mpll_288", "mpll_216", "mpll_172", "mpll_144",
					     "mpll_123", "mpll_124", "mpll_86", "pll_rv1";
			clock-rates = <384000000>, <320000000>, <160000000>, <192000000>,
			              <240000000>, <480000000>, <432000000>, <345000000>,
			              <288000000>, <216000000>, <172000000>, <144000000>,
			              <123000000>, <124000000>, <86000000>, <0>;
			clock-upstreams = <1>, <1>, <0>, <0>,
					  <0>, <0>, <0>, <0>,
					  <0>, <0>, <0>, <0>,
					  <0>, <0>, <0>, <0>;
			clocks = <&xtal24>, <&upll0>; /*<&utmi>;*/
		};

		gpio: gpio@1f207800 {
			#gpio-cells = <2>;
			reg = <0x1f207800 0x200>;
			gpio-controller;
			status = "disabled";
		};
		
		pinctrl: pinctrl@1f203c00 {
			reg = <0x1f203c00 0x200>;
			pm_uart_pins: pm_uart {
				function = "pm_uart";
				groups = "pm_uart";
			};
			pm_spi_pins: pm_spi {
				function = "pm_spi";
				groups = "pm_spi";
			};
			emac_pins: eth {
				function = "eth";
				groups = "eth";
			};
			fuart_pins: fuart {
				function = "fuart";
				groups = "fuart";
			};
			fuart_rx_tx_rts_pins: fuart_rx_tx_rts {
				function = "fuart";
				groups = "fuart_rx_tx_rts";
			};
			uart1_pins: uart1 {
				function = "uart1";
				groups = "fuart_cts_rts";
			};
			uart1_cts_pins: uart1_cts {
				function = "uart1";
				groups = "fuart_cts";
			};
			i2c0_pins: i2c0 {
				function = "i2c0";
				groups = "i2c0";
			};
			i2c1_pins: i2c1 {
				function = "i2c1";
				groups = "i2c1";
			};
			spi0_spi0_pins: spi0_spi0 {
				function = "spi0";
				groups = "spi0";
			};
			spi0_fuart_pins: spi0_fuart {
				function = "spi0";
				groups = "fuart";
			};
			spi1_sd_d0_d1_d2_d3_pins: spi1_sd_d0_d1_d2_d3 {
				function = "spi1";
				groups = "sd_d0_d1_d2_d3";
			};
			sdio_pins: sdio {
				function = "sdio";
				groups = "sd";
				bias-pull-up;
			};
			usb_pins: usb {
				function = "usb";
				groups = "usb";
			};
			usb1_pins: usb1 {
				function = "usb1";
				groups = "usb1";
			};
		};

		pm_uart: uart@1f221000 {
			compatible = "mstar,msc313-uart";
			reg = <0x1f221000 0x100>;
			reg-shift = <3>;
			clocks = <&clkgen_mux_uart 0>;
			interrupts-extended = <&intc_irq 34 IRQ_TYPE_LEVEL_HIGH>;
			pinctrl-names = "default";
			pinctrl-0 = <&pm_uart_pins>;
			status = "disabled";
		};

		uart1: uart@1f221200 {
			compatible = "mstar,msc313-uart";
			reg = <0x1f221200 0x100>;
			interrupts-extended = <&intc_irq 35 IRQ_TYPE_LEVEL_HIGH>;
			reg-shift = <3>;
			clocks = <&clkgen_mux_uart 1>;
			status = "disabled";
		};

		mspi0: mspi@1f222100 {
			compatible = "mstar,msc313-spi";
			reg = <0x1f222100 0x100>;
			interrupt-parent = <&intc_irq>;
			interrupts = <38 IRQ_TYPE_LEVEL_HIGH>;
			status = "disabled";
		};

		mspi1: mspi@1f222300 {
			compatible = "mstar,msc313-spi";
			reg = <0x1f222300 0x100>;
			interrupt-parent = <&intc_irq>;
			interrupts = <39 IRQ_TYPE_LEVEL_HIGH>;
			status = "disabled";
		};

		i2c0: i2c0@1f223000 {
			compatible = "mstar,msc313e-i2c";
			reg = <0x1f223000 0x200>;
			interrupt-parent = <&intc_irq>;
			interrupts = <36 IRQ_TYPE_LEVEL_HIGH>;
			#address-cells = <1>;
			#size-cells = <0>;
			clocks = <&clkgen_mux_miic 0>;
			clock-names = "i2c_clk";
			pinctrl-names = "default";
			pinctrl-0 = <&i2c0_pins>;
			status = "disabled";
		};

		i2c1: i2c1@1f223200 {
			compatible = "mstar,msc313e-i2c";
			reg = <0x1f223200 0x200>;
			interrupt-parent = <&intc_irq>;
			interrupts = <37 IRQ_TYPE_LEVEL_HIGH>;
			#address-cells = <1>;
			#size-cells = <0>;
			clocks = <&clkgen_mux_miic 1>;
			clock-names = "i2c_clk";
			pinctrl-names = "default";
			pinctrl-0 = <&i2c1_pins>;
			status = "disabled";
		};

		/* csi - camera interface */
		csi: csi@1f240800 {
			reg = <0x1f240800 0x200>;
			interrupts-extended = <&intc_irq 32 IRQ_TYPE_LEVEL_HIGH>;
		};

		/* pnl - RGB lcd driver? */
		/* different address on m5? */
		pnl: pnl@1f243400 {
			compatible = "mstar,pnl";
			reg = <0x1f243400 0x200>;
			ports {
				#address-cells = <1>;
				#size-cells = <0>;
				pnl_in: port@0 {
					#address-cells = <1>;
					#size-cells = <0>;
					reg = <0>;

					pnl_in_gop0: endpoint@0 {
						reg = <0>;
						remote-endpoint = <&gop0_out_pnl>;
					};
				};
			};
		};

		/* gop - framebuffer */
		gop0: gop@1f246200 {
			compatible = "mstar,gop";
			reg = <0x1f246200 0x400>;
			interrupt-names = "gop";
			interrupts-extended = <&intc_irq 50 IRQ_TYPE_LEVEL_HIGH>;
			clocks = <&clkgen_mux_gop 0>;
			ports {
				#address-cells = <1>;
				#size-cells = <0>;
				gop0_out: port@0 {
					#address-cells = <1>;
					#size-cells = <0>;
					reg = <0>;
		
					gop0_out_pnl: endpoint@1 {
						reg = <1>;
						remote-endpoint = <&pnl_in_gop0>;
					};
				};
			};
		};

		/*
		gop1: gop@0x1f246800 {
		
		};
		
		gop2: gop@0x1f246e00 {
		
		};*/

		display@0 {
			compatible = "mstar,drm";
			ports = <&gop0_out>;
		};

		upll0: upll@1f284000 {
			#clock-cells = <0>;
			compatible = "mstar,msc313-upll";
			reg = <0x1f284000 0x20>;
			clocks = <&xtal12>;
		};

		usbphy0: usbphy@0 {
			#phy-cells = <1>;
			compatible = "mstar,msc313-usb-phy";
			clocks = <&xtal12>;
			mstar,utmi = <&utmi0>;
			mstar,usbc = <&usbc0>;
			interrupts-extended = <&intc_irq 30 IRQ_TYPE_LEVEL_HIGH>;
			/*pinctrl-names = "default";
			pinctrl-0 = <&usb_pins>;*/
			status = "disabled";
		};

		utmi0: utmi@1f284200 {
			compatible = "syscon";
			reg = <0x1f284200 0x80>;
		};

		usbc0: usbc@1f284600 {
			compatible = "syscon";
			reg = <0x1f284600 0x20>;
		};

		uhc0: uhc@1f284800 {
			compatible = "mstar,msc313-ehci";
			reg = <0x1f284800 0x200>;
			interrupts-extended = <&intc_irq 31 IRQ_TYPE_LEVEL_HIGH>;
			phys = <&usbphy0 0>;
			phy-names = "usb";
			mstar,usbc = <&usbc0>;
			status = "disabled";
		};

		utmi1: utmi@1f285200 {
			compatible = "syscon";
			reg = <0x1f285200 0x80>;
		};

		usbc1: usbc@1f286200 {
			compatible = "syscon";
			reg = <0x1f286200 0x20>;
		};

		usbphy1: usbphy@1 {
			#phy-cells = <1>;
			compatible = "mstar,msc313-usb-phy";
			clocks = <&xtal12>;
			mstar,utmi = <&utmi1>;
			mstar,usbc = <&usbc1>;
		};

		uhc1: uhc@1f286400 {
			compatible = "mstar,msc313-ehci";
			reg = <0x1f286400 0x200>;
			interrupts-extended = <&intc_irq 55 IRQ_TYPE_LEVEL_HIGH>;
			phys = <&usbphy1 0>;
			phy-names = "usb";
			mstar,usbc = <&usbc1>;
			status = "disabled";
		};

		sram: sram@a0000000 {
			compatible = "mmio-sram";
			reg = <0xa0000000 0x10000>;
		};
	};
};
